# GD32E501 register map
File version: 1.0
CPU: CM33 r0p4, little endian, MPU, FPU, 4 interrupt priority bits
Registers are 32-bit, read-write, reset 0x0 unless marked. A register's access mark holds for its fields unless they carry their own. Offsets are from the block's base; [hi:lo] are bit positions; {n}, {i} and the like mark numbered series; 'fields as' and 'values as' point back to an identical list.

## DBGMCU — Debug support
Base 0xE0044000
0x00 ID ro — MCU Device ID Code Register
  [31:0] ID_CODE — DBG ID code register
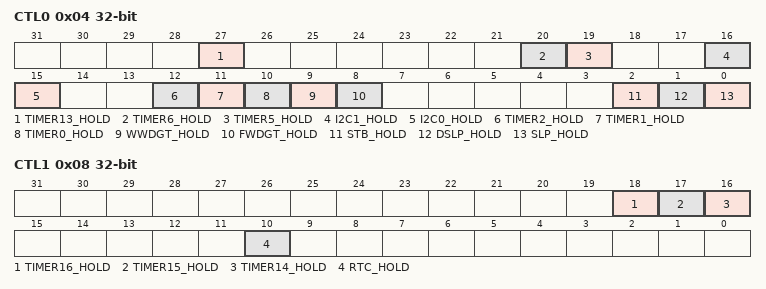
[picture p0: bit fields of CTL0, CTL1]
0x04 CTL0 — Debug Control Register 0
  [27] TIMER13_HOLD — Timer 13 hold bit
  [20] TIMER6_HOLD — Timer 6 hold bit
  [19] TIMER5_HOLD — Timer 5 hold bit
  [16] I2C1_HOLD — I2C1 hold bit
  [15] I2C0_HOLD — I2C0 hold bit
  [12] TIMER2_HOLD — Timer 2 hold bit
  [11] TIMER1_HOLD — Timer 1 hold bit
  [10] TIMER0_HOLD — Timer 0 hold bit
  [9] WWDGT_HOLD — WWDGT hold bit
  [8] FWDGT_HOLD — FWDGT hold bit
  [2] STB_HOLD — Standby mode hold Mode
  [1] DSLP_HOLD — DEEPSLEEP mode hold Mode
  [0] SLP_HOLD — Sleep mode hold register
0x08 CTL1 — Debug Control Register 1
  [18] TIMER16_HOLD — Timer 16 hold bit
  [17] TIMER15_HOLD — Timer 15 hold bit
  [16] TIMER14_HOLD — Timer 14 hold bit
  [10] RTC_HOLD — RTC hold bit

## DMA — DMA controller
Base 0x40020000
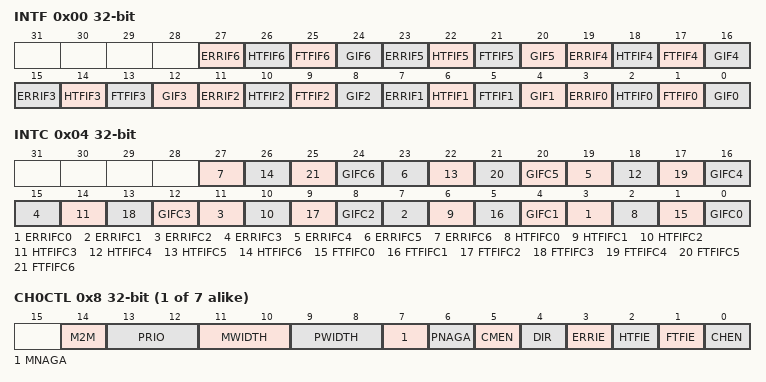
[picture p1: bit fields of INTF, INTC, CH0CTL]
0x00 INTF ro — DMA interrupt flag register (DMA_INTF)
  [4n+3] ERRIF{n} (n=0..6) — Channel {n} Error flag
  [4n+2] HTFIF{n} (n=0..6) — Channel {n} Half Transfer Finish flag
  [4n+1] FTFIF{n} (n=0..6) — Channel {n} Full Transfer Finish flag
  [4n] GIF{n} (n=0..6) — Channel {n} Global interrupt flag
0x04 INTC wo — DMA interrupt flag clear register (DMA_INTC)
  [4n+3] ERRIFC{n} (n=0..6) — Channel {n} Error clear
  [4n+2] HTFIFC{n} (n=0..6) — Channel {n} Half Transfer clear
  [4n+1] FTFIFC{n} (n=0..6) — Channel {n} Full Transfer Finish clear
  [4n] GIFC{n} (n=0..6) — Channel {n} Global interrupt flag clear
{0x8+0x14*i} CH{i}CTL (i=0..6) — DMA channel configuration register (DMA_CH{i}CTL)
  [14] M2M — Memory to memory mode
  [13:12] PRIO — Priority Level of this channel
  [11:10] MWIDTH — Transfer data size of memory
  [9:8] PWIDTH — Transfer data size of peripheral
  [7] MNAGA — Next address generation algorithm of memory
  [6] PNAGA — Next address generation algorithm of peripheral
  [5] CMEN — Circular mode enable
  [4] DIR — Transfer direction
  [3] ERRIE — Error interrupt enable
  [2] HTFIE — Half Transfer Finish interrupt enable
  [1] FTFIE — Full Transfer Finish interrupt enable
  [0] CHEN — Channel enable
{0xC+0x14*i} CH{i}CNT (i=0..6) — DMA channel {i} counter register
  [15:0] CNT — Transfer counter
{0x10+0x14*i} CH{i}PADDR (i=0..6) — DMA channel {i} peripheral base address register
  [31:0] PADDR — Peripheral base address
{0x14+0x14*i} CH{i}MADDR (i=0..6) — DMA channel {i} memory base address register
  [31:0] MADDR — Memory address

## EXTI — External interrupt/event controller
Base 0x40010400
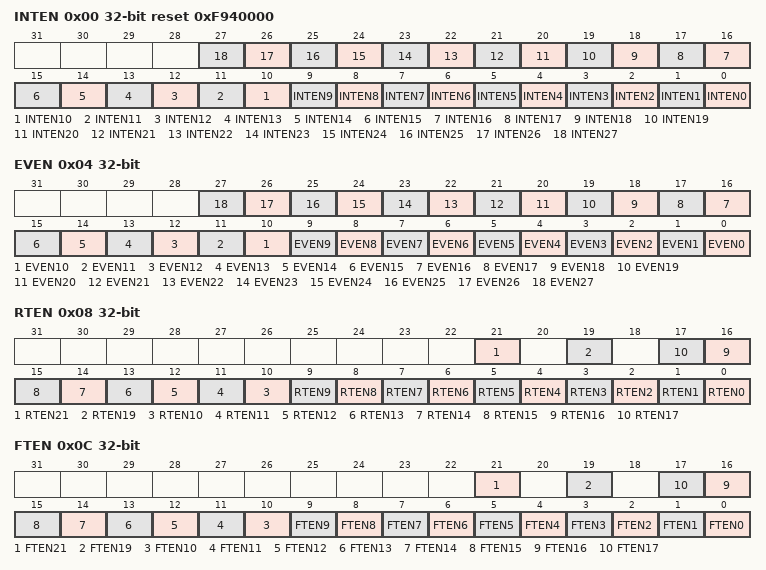
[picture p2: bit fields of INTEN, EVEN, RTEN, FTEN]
0x00 INTEN reset 0xF940000 — Interrupt enable register (EXTI_INTEN)
  [n] INTEN{n} (n=0..27) — Enable Interrupt on line {n}
0x04 EVEN — Event enable register (EXTI_EVEN)
  [n] EVEN{n} (n=0..27) — Enable Event on line {n}
0x08 RTEN — Rising edge trigger enable register (EXTI_RTEN)
  [21] RTEN21 — Rising trigger event configuration of line 21
  [19] RTEN19 — Rising trigger event configuration of line 19
  [n] RTEN{n} (n=0..17) — Rising trigger event configuration of line {n}
0x0C FTEN — Falling egde trigger enable register (EXTI_FTEN)
  [21] FTEN21 — Falling trigger event configuration of line 21
  [19] FTEN19 — Falling trigger event configuration of line 19
  [n] FTEN{n} (n=0..17) — Falling trigger event configuration of line {n}
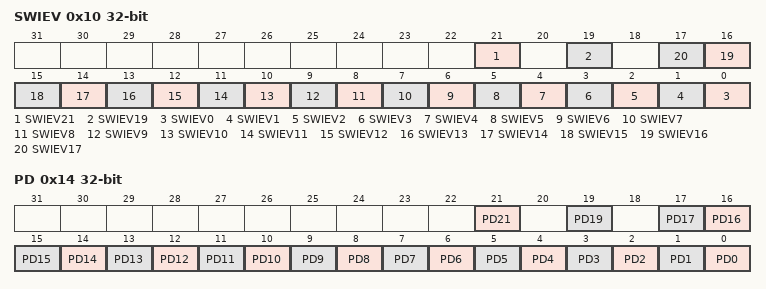
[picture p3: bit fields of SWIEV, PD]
0x10 SWIEV — Software interrupt event register (EXTI_SWIEV)
  [21] SWIEV21 — Software Interrupt on line 21
  [19] SWIEV19 — Software Interrupt on line 19
  [n] SWIEV{n} (n=0..17) — Software Interrupt on line {n}
0x14 PD — Pending register (EXTI_PD)
  [21] PD21 — Pending bit 21
  [19] PD19 — Pending bit 19
  [n] PD{n} (n=0..17) — Pending bit {n}

## FMC
Base 0x40022000
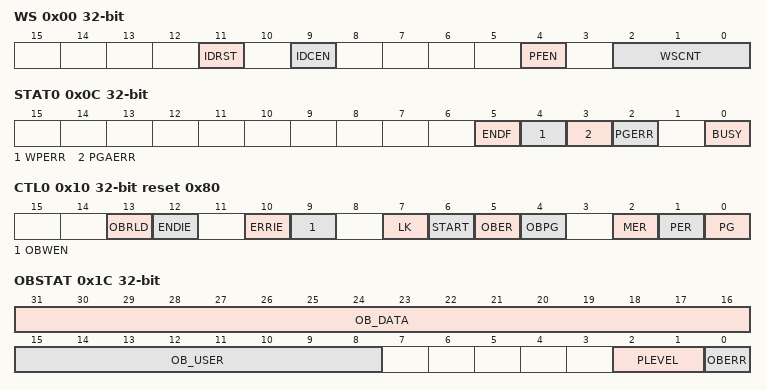
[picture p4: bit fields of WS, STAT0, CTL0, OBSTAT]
0x00 WS — wait state register
  [11] IDRST — Cache reset
  [9] IDCEN — Cache enable
  [4] PFEN — Pre-fetch enable
  [2:0] WSCNT — wait state counter register
0x04 KEY0 wo — Unlock key register
  [31:0] KEY — FMC_CTL0 unlock register
0x08 OBKEY wo — Option byte unlock key register
  [31:0] OBKEY — FMC_ CTL0 option bytes operation unlock register
0x0C STAT0 access per field — Status register
  [5] ENDF rw — End of operation flag bit
  [4] WPERR rw — Erase/Program protection error flag bit
  [3] PGAERR rw — Program alignment error flag bit
  [2] PGERR rw — Program error flag bit
  [0] BUSY ro — The flash is busy bit
0x10 CTL0 reset 0x80 — Control register
  [13] OBRLD — Option byte reload bit
  [12] ENDIE — End of operation interrupt enable bit
  [10] ERRIE — Error interrupt enable bit
  [9] OBWEN — Option byte erase/program enable bit
  [7] LK — FMC_CTL lock bit
  [6] START — Send erase command to FMC bit
  [5] OBER — Option bytes erase command bit
  [4] OBPG — Option bytes program command bit
  [2] MER — Main flash mass erase for bank0 command bit
  [1] PER — Main flash page erase for bank0 command bit
  [0] PG — Main flash program for bank0 command bit
0x14 ADDR0 — Address register
  [31:0] ADDR — Flash erase/program command address bits
0x1C OBSTAT ro — Option byte status register
  [31:16] OB_DATA — Store DATA[15:0] of option bytes block after system reset
  [15:8] OB_USER — Store USER of option bytes block after system reset
  [2:1] PLEVEL — Option bytes security protection level
  [0] OBERR — Option bytes read error bit
0x20 WP ro — Erase/Program Protection register
  [31:0] OB_WP — Store WP[15:0] of option bytes block after system reset
0x44 KEY1 wo — Unlock key register
  [31:0] KEY — FMC_CTL1 unlock register
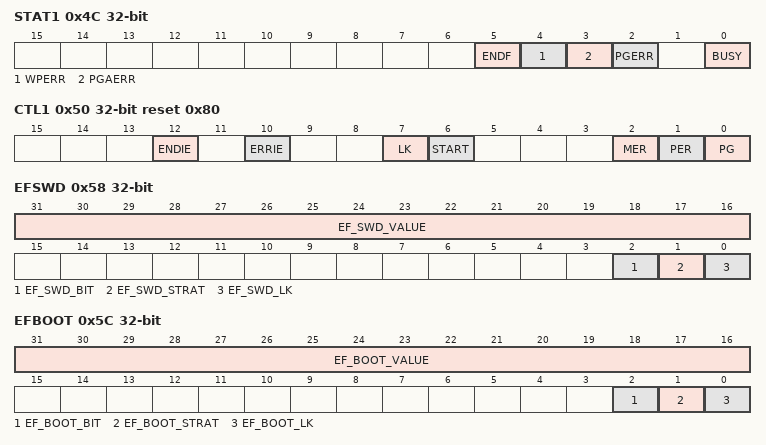
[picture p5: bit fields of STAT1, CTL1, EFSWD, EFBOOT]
0x4C STAT1 access per field — Status register
  fields as STAT0
0x50 CTL1 reset 0x80 — Control register
  [12] ENDIE — End of operation interrupt enable bit
  [10] ERRIE — Error interrupt enable bit
  [7] LK — FMC_CTL lock bit
  [6] START — Send erase command to FMC bit
  [2] MER — Main flash mass erase command bit
  [1] PER — Main flash page erase command bit
  [0] PG — Main flash page program command bit
0x54 ADDR1 — Address register
  [31:0] ADDR — Flash erase/program command address bits
0x58 EFSWD access not given — Efuse SWD protection register
  [31:16] EF_SWD_VALUE — This field load EF_SWD_VALUE from e-flash when system reset
  [2] EF_SWD_BIT — Read only, when EF_SWD_VALUE is 0x33CC, set 1
  [1] EF_SWD_STRAT — This bit triggers an operation after writing EF_SWD_VALUE to e-flash
  [0] EF_SWD_LK — Read only，when EF_SWD_VALUE if not 0xFFFF, set EF_SWD_LK 1
0x5C EFBOOT access not given — Efuse BOOT protection register
  [31:16] EF_BOOT_VALUE — This field load EF_BOOT_VALUE from e-flash when system reset
  [2] EF_BOOT_BIT — Read only, when EF_BOOT_VALUE is 0x33CC, set 1
  [1] EF_BOOT_STRAT — This bit triggers an operation after writing EF_BOOT_VALUE to e-flash
  [0] EF_BOOT_LK — Read only，when EF_BOOT_VALUE if not 0xFFFF, set EF_BOOT_LK 1
0x100 PID ro — Product ID register
  [31:0] PID — Product reserved ID code register
